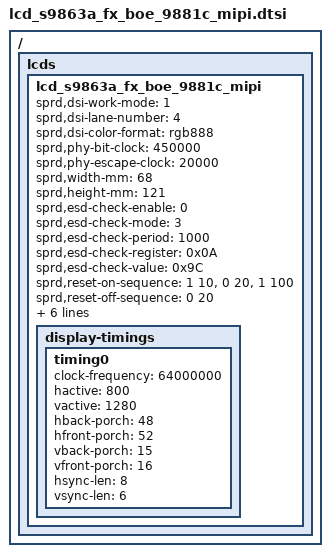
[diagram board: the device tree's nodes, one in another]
/ { lcds {
	lcd_s9863a_fx_boe_9881c_mipi: lcd_s9863a_fx_boe_9881c_mipi {

		sprd,dsi-work-mode = <1>;
		sprd,dsi-lane-number = <4>;
		sprd,dsi-color-format = "rgb888";

		sprd,phy-bit-clock = <450000>;
		sprd,phy-escape-clock = <20000>;

		sprd,width-mm = <68>;
		sprd,height-mm = <121>;

		sprd,esd-check-enable = <0>;
		sprd,esd-check-mode = <3>;
		sprd,esd-check-period = <1000>;
		sprd,esd-check-register = <0x0A>;
		sprd,esd-check-value = <0x9C>;

		sprd,reset-on-sequence = <1 10>, <0 20>, <1 100>;
		sprd,reset-off-sequence = <0 20>;

		sprd,initial-command = [

		 39 00 00 04 FF 98 81 03 
//GIP_1
		 23 00 00 02 01 00 
		 23 00 00 02 02 00 
		 23 00 00 02 03 73 
		 23 00 00 02 04 00 
		 23 00 00 02 05 00 
		 23 00 00 02 06 08 
		 23 00 00 02 07 00 
		 23 00 00 02 08 00 
		 23 00 00 02 09 00 
		 23 00 00 02 0A 01 
		 23 00 00 02 0B 01 
		 23 00 00 02 0C 00 
		 23 00 00 02 0D 01 
		 23 00 00 02 0E 01 
		 23 00 00 02 0F 00 
		 23 00 00 02 10 00 
		 23 00 00 02 11 00 
		 23 00 00 02 12 00 
		 23 00 00 02 13 1F //00
		 23 00 00 02 14 1F 
		 23 00 00 02 15 00 
		 23 00 00 02 16 00 
		 23 00 00 02 17 00 
		 23 00 00 02 18 00 
		 23 00 00 02 19 00 
		 23 00 00 02 1A 00 
		 23 00 00 02 1B 00 
		 23 00 00 02 1C 00 
		 23 00 00 02 1D 00 
		 23 00 00 02 1E 40 
		 23 00 00 02 1F C0 
		 23 00 00 02 20 06 
		 23 00 00 02 21 01 
		 23 00 00 02 22 06 
		 23 00 00 02 23 01 
		 23 00 00 02 24 88 
		 23 00 00 02 25 88 
		 23 00 00 02 26 00 
		 23 00 00 02 27 00 
		 23 00 00 02 28 3B 
		 23 00 00 02 29 03 
		 23 00 00 02 2A 00 
		 23 00 00 02 2B 00 
		 23 00 00 02 2C 00 
		 23 00 00 02 2D 00 
		 23 00 00 02 2E 00 
		 23 00 00 02 2F 00 
		 23 00 00 02 30 00 
		 23 00 00 02 31 00 
		 23 00 00 02 32 00 
		 23 00 00 02 33 00 
		 23 00 00 02 34 00   // GPWR1/2 non overlap time 2.62us
		 23 00 00 02 35 00 
		 23 00 00 02 36 00 
		 23 00 00 02 37 00 
		 23 00 00 02 38 00 
		 23 00 00 02 39 00 
		 23 00 00 02 3A 00 
		 23 00 00 02 3B 00 
		 23 00 00 02 3C 00 
		 23 00 00 02 3D 00 
		 23 00 00 02 3E 00 
		 23 00 00 02 3F 00 
		 23 00 00 02 40 00 
		 23 00 00 02 41 00 
		 23 00 00 02 42 00 
		 23 00 00 02 43 00 
		 23 00 00 02 44 00 
 //GIP_2                         
		 23 00 00 02 50 01 
		 23 00 00 02 51 23 
		 23 00 00 02 52 45 
		 23 00 00 02 53 67 
		 23 00 00 02 54 89 
		 23 00 00 02 55 AB 
		 23 00 00 02 56 01 
		 23 00 00 02 57 23 
		 23 00 00 02 58 45 
		 23 00 00 02 59 67 
		 23 00 00 02 5A 89 
		 23 00 00 02 5B AB 
		 23 00 00 02 5C CD 
		 23 00 00 02 5D EF 
//GIP_3                         
		 23 00 00 02 5E 00 
		 23 00 00 02 5F 01 
		 23 00 00 02 60 01 
		 23 00 00 02 61 06 
		 23 00 00 02 62 06 
		 23 00 00 02 63 07 
		 23 00 00 02 64 07 
		 23 00 00 02 65 00 
		 23 00 00 02 66 00 
		 23 00 00 02 67 02 
		 23 00 00 02 68 02 
		 23 00 00 02 69 05 
		 23 00 00 02 6A 05 
		 23 00 00 02 6B 02 
		 23 00 00 02 6C 0D 
		 23 00 00 02 6D 0D 
		 23 00 00 02 6E 0C 
		 23 00 00 02 6F 0C 
		 23 00 00 02 70 0F 
		 23 00 00 02 71 0F 
		 23 00 00 02 72 0E 
		 23 00 00 02 73 0E 
		 23 00 00 02 74 02 
		 23 00 00 02 75 01 
		 23 00 00 02 76 01 
		 23 00 00 02 77 06 
		 23 00 00 02 78 06 
		 23 00 00 02 79 07 
		 23 00 00 02 7A 07 
		 23 00 00 02 7B 00 
		 23 00 00 02 7C 00 
		 23 00 00 02 7D 02 
		 23 00 00 02 7E 02 
		 23 00 00 02 7F 05 
		 23 00 00 02 80 05 
		 23 00 00 02 81 02 
		 23 00 00 02 82 0D 
		 23 00 00 02 83 0D 
		 23 00 00 02 84 0C 
		 23 00 00 02 85 0C 
		 23 00 00 02 86 0F 
		 23 00 00 02 87 0F 
		 23 00 00 02 88 0E 
		 23 00 00 02 89 0E 
		 23 00 00 02 8A 02                             
//Page 4 command;    
		 39 00 00 04 FF 98 81 04 
	//	 23 00 00 02 2F 01     //zice
		// 23 00 00 02 3B C0      // ILI4003D sel
		 23 00 00 02 6C 15         //Set VCORE voltage =1.5V
		 23 00 00 02 6E 2A         //di_pwr_reg=0 for power mode 2A //VGH clamp 18V
		 23 00 00 02 6F 33     //45 //pumping ratio VGH=5x VGL=-3x
		 23 00 00 02 8D 1B         //VGL clamp -10V
		 23 00 00 02 87 BA         //ESD
		 23 00 00 02 3A 24         //POWER SAVING
		 23 00 00 02 26 76 
		 23 00 00 02 B2 D1 
// Page 1 command              
		 39 00 00 04 FF 98 81 01 
		 23 00 00 02 22 0A         //BGR  SS
		 23 00 00 02 31 00         //Zigzag type3 inversion
		// 23 00 00 02 40 53         // ILI4003D sel
		 23 00 00 02 43 66 
		 23 00 00 02 53 42 
		 23 00 00 02 50 87 
		 23 00 00 02 51 82 
		 23 00 00 02 60 15 
		 23 00 00 02 61 01 
		 23 00 00 02 62 0C 
		 23 00 00 02 63 00 
 // Gamma P                      
		 23 00 00 02 A0 00 
		 23 00 00 02 A1 13         //VP251
		 23 00 00 02 A2 23         //VP247
		 23 00 00 02 A3 14         //VP243
		 23 00 00 02 A4 16         //VP239
		 23 00 00 02 A5 29         //VP231
		 23 00 00 02 A6 1E         //VP219
		 23 00 00 02 A7 1D         //VP203
		 23 00 00 02 A8 86         //VP175
		 23 00 00 02 A9 1E         //VP144
		 23 00 00 02 AA 29         //VP111
		 23 00 00 02 AB 74         //VP80
		 23 00 00 02 AC 19         //VP52
		 23 00 00 02 AD 17         //VP36
		 23 00 00 02 AE 4B         //VP24
		 23 00 00 02 AF 20         //VP16
		 23 00 00 02 B0 26         //VP12
		 23 00 00 02 B1 4C         //VP8
		 23 00 00 02 B2 5D         //VP4
		 23 00 00 02 B3 3F         //VP0
// Gamma N                      
		 23 00 00 02 C0 00         //VN255 GAMMA N
		 23 00 00 02 C1 13         //VN251
		 23 00 00 02 C2 23         //VN247
		 23 00 00 02 C3 14         //VN243
		 23 00 00 02 C4 16         //VN239
		 23 00 00 02 C5 29         //VN231
		 23 00 00 02 C6 1E         //VN219
		 23 00 00 02 C7 1D         //VN203
		 23 00 00 02 C8 86         //VN175
		 23 00 00 02 C9 1E         //VN144
		 23 00 00 02 CA 29         //VN111
		 23 00 00 02 CB 74         //VN80
		 23 00 00 02 CC 19         //VN52
		 23 00 00 02 CD 17         //VN36
		 23 00 00 02 CE 4B         //VN24
		 23 00 00 02 CF 20         //VN16
		 23 00 00 02 D0 26         //VN12
		 23 00 00 02 D1 4C         //VN8
		 23 00 00 02 D2 5D         //VN4
		 23 00 00 02 D3 3F         //VN0
		 39 00 00 04 FF 98 81 00 	
						
			23 00 00 02 35 00 
			13 78 00 01 11
			13 64 00 01 29
			];
		sprd,sleep-in-command = [
			13 0A 00 01 28
			13 78 00 01 10
			];
		sprd,sleep-out-command = [
			13 78 00 01 11
			13 64 00 01 29
			];

		display-timings {
			timing0 {
			clock-frequency = <64000000>;
			hactive = <800>;
			vactive = <1280>;
			hback-porch = <48>;
			hfront-porch = <52>;
			vback-porch = <15>;
			vfront-porch = <16>;
			hsync-len = <8>;
			vsync-len = <6>;
			};
		};
	};
};};

